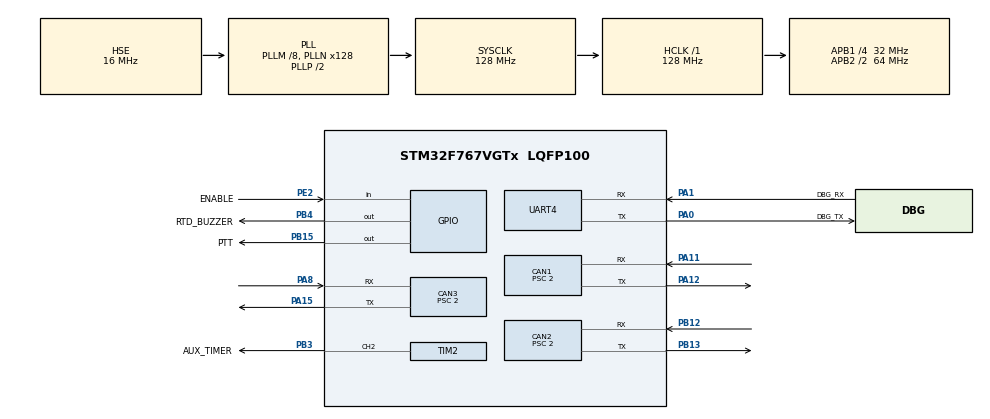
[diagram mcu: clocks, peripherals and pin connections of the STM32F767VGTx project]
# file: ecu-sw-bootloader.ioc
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CAN1.BS1=CAN_BS1_13TQ
CAN1.BS2=CAN_BS2_2TQ
CAN1.CalculateBaudRate=1000000
CAN1.CalculateTimeBit=1000
CAN1.CalculateTimeQuantum=62.5
CAN1.Prescaler=2
CAN2.BS1=CAN_BS1_13TQ
CAN2.BS2=CAN_BS2_2TQ
CAN2.CalculateBaudRate=1000000
CAN2.CalculateTimeBit=1000
CAN2.CalculateTimeQuantum=62.5
CAN2.Prescaler=2
CAN3.BS1=CAN_BS1_13TQ
CAN3.BS2=CAN_BS2_2TQ
CAN3.CalculateBaudRate=1000000
CAN3.CalculateTimeBit=1000
CAN3.CalculateTimeQuantum=62.5
CAN3.Prescaler=2
CORTEX_M7.default_mode_Activation=1
Mcu.Family=STM32F7
Mcu.Name=STM32F767VGTx
Mcu.Package=LQFP100
NVIC.CAN1_RX0_IRQn=true\:0\:0\:false\:false\:true\:true\:true\:true
NVIC.CAN1_RX1_IRQn=true\:0\:0\:false\:false\:true\:true\:true\:true
NVIC.CAN1_TX_IRQn=true\:0\:0\:false\:false\:true\:true\:true\:true
NVIC.CAN2_RX0_IRQn=true\:0\:0\:false\:false\:true\:true\:true\:true
NVIC.CAN2_RX1_IRQn=true\:0\:0\:false\:false\:true\:true\:true\:true
NVIC.CAN2_TX_IRQn=true\:0\:0\:false\:false\:true\:true\:true\:true
NVIC.CAN3_RX0_IRQn=true\:0\:0\:false\:false\:true\:true\:true\:true
NVIC.CAN3_RX1_IRQn=true\:0\:0\:false\:false\:true\:true\:true\:true
NVIC.CAN3_TX_IRQn=true\:0\:0\:false\:false\:true\:true\:true\:true
NVIC.PriorityGroup=NVIC_PRIORITYGROUP_4
NVIC.TIM2_IRQn=true\:0\:0\:false\:false\:true\:true\:true\:true
PA0/WKUP.GPIO_Label=DBG_TX
PA0/WKUP.Mode=Asynchronous
PA0/WKUP.Signal=UART4_TX
PA1.GPIO_Label=DBG_RX
PA1.Mode=Asynchronous
PA1.Signal=UART4_RX
PA11.Mode=CAN_Activate
PA11.Signal=CAN1_RX
PA12.Mode=CAN_Activate
PA12.Signal=CAN1_TX
PA13.GPIO_Label=SWDIO
PA13.Mode=Serial_Wire
PA13.Signal=SYS_JTMS-SWDIO
PA14.GPIO_Label=SWCLK
PA14.Mode=Serial_Wire
PA14.Signal=SYS_JTCK-SWCLK
PA15.Mode=CAN_Activate
PA15.Signal=CAN3_TX
PA8.Mode=CAN_Activate
PA8.Signal=CAN3_RX
PB12.Mode=CAN_Activate
PB12.Signal=CAN2_RX
PB13.Mode=CAN_Activate
PB13.Signal=CAN2_TX
PB15.GPIO_Label=PTT
PB15.Signal=GPIO_Output
PB3.GPIO_Label=AUX_TIMER
PB3.Signal=S_TIM2_CH2
PB4.GPIO_Label=RTD_BUZZER
PB4.Signal=GPIO_Output
PE2.GPIO_Label=ENABLE
PE2.Signal=GPIO_Input
PH0/OSC_IN.Mode=HSE-External-Oscillator
PH0/OSC_IN.Signal=RCC_OSC_IN
PH1/OSC_OUT.Mode=HSE-External-Oscillator
PH1/OSC_OUT.Signal=RCC_OSC_OUT
ProjectManager.HeapSize=0x200
ProjectManager.StackSize=0x400
ProjectManager.TargetToolchain=Makefile
RCC.AHBFreq_Value=128000000
RCC.APB1CLKDivider=RCC_HCLK_DIV4
RCC.APB1Freq_Value=32000000
RCC.APB1TimFreq_Value=64000000
RCC.APB2CLKDivider=RCC_HCLK_DIV2
RCC.APB2Freq_Value=64000000
RCC.APB2TimFreq_Value=128000000
RCC.CortexFreq_Value=128000000
RCC.HCLKFreq_Value=128000000
RCC.HSE_VALUE=16000000
RCC.HSI_VALUE=16000000
RCC.LSE_VALUE=32768
RCC.PLLM=8
RCC.PLLN=128
RCC.PLLSourceVirtual=RCC_PLLSOURCE_HSE
RCC.SYSCLKFreq_VALUE=128000000
RCC.SYSCLKSource=RCC_SYSCLKSOURCE_PLLCLK
RCC.USBFreq_Value=128000000
RCC.VCOOutputFreq_Value=256000000
SH.S_TIM2_CH2.0=TIM2_CH2,PWM Generation2 CH2
TIM2.Channel-PWM\ Generation2\ CH2=TIM_CHANNEL_2
board=custom

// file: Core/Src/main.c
/* USER CODE BEGIN Header */
/**
  ******************************************************************************
  * @file           : main.c
  * @brief          : Main program body
  ******************************************************************************
  * @attention
  *
  * Copyright (c) 2025 STMicroelectronics.
  * All rights reserved.
  *
  * This software is licensed under terms that can be found in the LICENSE file
  * in the root directory of this software component.
  * If no LICENSE file comes with this software, it is provided AS-IS.
  *
  ******************************************************************************
  */
/* USER CODE END Header */
#include "main.h"
#include "can.h"
#include "tim.h"
#include "usart.h"
#include "gpio.h"

/* USER CODE BEGIN Includes */
#include "boot.h"
/* USER CODE END Includes */

void SystemClock_Config(void);
static void MPU_Config(void);

/* USER CODE BEGIN 0 */
static void VectorBase_Config(void) {
    /* The constant array with vectors of the vector table is declared externally in the
   * c-startup code.
   */
    extern const unsigned long g_pfnVectors[];

    /* Remap the vector table to where the vector table is located for this program. */
    SCB->VTOR = (unsigned long)&g_pfnVectors[0];
}
/* USER CODE END 0 */

int main(void) {

    /* USER CODE BEGIN 1 */
    VectorBase_Config();

    /* USER CODE END 1 */

    /* MPU Configuration--------------------------------------------------------*/
    MPU_Config();

    /* MCU Configuration--------------------------------------------------------*/

    /* Reset of all peripherals, Initializes the Flash interface and the Systick. */
    HAL_Init();

    /* Configure the system clock */
    SystemClock_Config();

    /* Initialize all configured peripherals */
    MX_GPIO_Init();
    MX_CAN1_Init();
    MX_CAN2_Init();
    MX_CAN3_Init();
    MX_UART4_Init();
    MX_TIM2_Init();
    /* USER CODE BEGIN 2 */
    BootInit();
    /* USER CODE END 2 */

    /* Infinite loop */
    /* USER CODE BEGIN WHILE */
    while (1) {
        BootTask();
        /* USER CODE END WHILE */

    }
}

void SystemClock_Config(void) {
    RCC_OscInitTypeDef RCC_OscInitStruct = { 0 };
    RCC_ClkInitTypeDef RCC_ClkInitStruct = { 0 };

    /** Configure the main internal regulator output voltage
  */
    __HAL_RCC_PWR_CLK_ENABLE();
    __HAL_PWR_VOLTAGESCALING_CONFIG(PWR_REGULATOR_VOLTAGE_SCALE3);

    /** Initializes the RCC Oscillators according to the specified parameters
  * in the RCC_OscInitTypeDef structure.
  */
    RCC_OscInitStruct.OscillatorType = RCC_OSCILLATORTYPE_HSE;
    RCC_OscInitStruct.HSEState = RCC_HSE_ON;
    RCC_OscInitStruct.PLL.PLLState = RCC_PLL_ON;
    RCC_OscInitStruct.PLL.PLLSource = RCC_PLLSOURCE_HSE;
    RCC_OscInitStruct.PLL.PLLM = 8;
    RCC_OscInitStruct.PLL.PLLN = 128;
    RCC_OscInitStruct.PLL.PLLP = RCC_PLLP_DIV2;
    RCC_OscInitStruct.PLL.PLLQ = 2;
    RCC_OscInitStruct.PLL.PLLR = 2;
    if (HAL_RCC_OscConfig(&RCC_OscInitStruct) != HAL_OK) {
        Error_Handler();
    }

    /** Initializes the CPU, AHB and APB buses clocks
  */
    RCC_ClkInitStruct.ClockType = RCC_CLOCKTYPE_HCLK | RCC_CLOCKTYPE_SYSCLK | RCC_CLOCKTYPE_PCLK1 | RCC_CLOCKTYPE_PCLK2;
    RCC_ClkInitStruct.SYSCLKSource = RCC_SYSCLKSOURCE_PLLCLK;
    RCC_ClkInitStruct.AHBCLKDivider = RCC_SYSCLK_DIV1;
    RCC_ClkInitStruct.APB1CLKDivider = RCC_HCLK_DIV4;
    RCC_ClkInitStruct.APB2CLKDivider = RCC_HCLK_DIV2;

    if (HAL_RCC_ClockConfig(&RCC_ClkInitStruct, FLASH_LATENCY_4) != HAL_OK) {
        Error_Handler();
    }
}

/* MPU Configuration */

void MPU_Config(void) {
    MPU_Region_InitTypeDef MPU_InitStruct = { 0 };

    /* Disables the MPU */
    HAL_MPU_Disable();

    /** Initializes and configures the Region and the memory to be protected
  */
    MPU_InitStruct.Enable = MPU_REGION_ENABLE;
    MPU_InitStruct.Number = MPU_REGION_NUMBER0;
    MPU_InitStruct.BaseAddress = 0x0;
    MPU_InitStruct.Size = MPU_REGION_SIZE_4GB;
    MPU_InitStruct.SubRegionDisable = 0x87;
    MPU_InitStruct.TypeExtField = MPU_TEX_LEVEL0;
    MPU_InitStruct.AccessPermission = MPU_REGION_NO_ACCESS;
    MPU_InitStruct.DisableExec = MPU_INSTRUCTION_ACCESS_DISABLE;
    MPU_InitStruct.IsShareable = MPU_ACCESS_SHAREABLE;
    MPU_InitStruct.IsCacheable = MPU_ACCESS_NOT_CACHEABLE;
    MPU_InitStruct.IsBufferable = MPU_ACCESS_NOT_BUFFERABLE;

    HAL_MPU_ConfigRegion(&MPU_InitStruct);
    /* Enables the MPU */
    HAL_MPU_Enable(MPU_PRIVILEGED_DEFAULT);
}

void Error_Handler(void) {
    __disable_irq();
    while (1) {
    }
}
